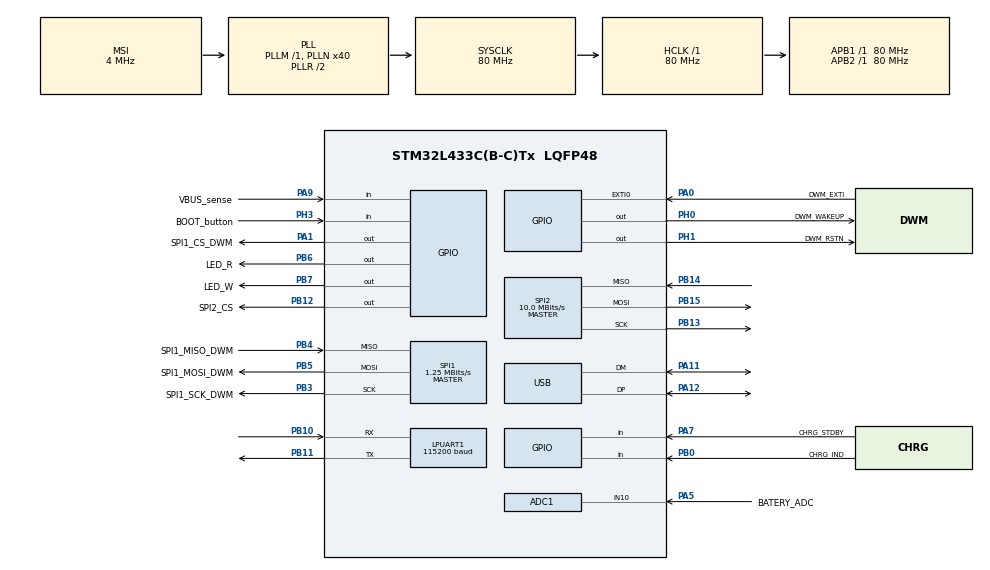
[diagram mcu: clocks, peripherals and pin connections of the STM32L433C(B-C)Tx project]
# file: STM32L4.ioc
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ADC1.Channel-1\#ChannelRegularConversion=ADC_CHANNEL_10
ADC1.ClockPrescaler=ADC_CLOCK_ASYNC_DIV256
ADC1.LowPowerAutoWait=ENABLE
ADC1.NbrOfConversionFlag=1
ADC1.OffsetNumber-1\#ChannelRegularConversion=ADC_OFFSET_NONE
ADC1.Rank-1\#ChannelRegularConversion=1
ADC1.Resolution=ADC_RESOLUTION_8B
ADC1.SamplingTime-1\#ChannelRegularConversion=ADC_SAMPLETIME_640CYCLES_5
ADC1.master=1
Dma.LPUART_RX.0.Direction=DMA_PERIPH_TO_MEMORY
Dma.LPUART_RX.0.Instance=DMA2_Channel7
Dma.LPUART_RX.0.MemDataAlignment=DMA_MDATAALIGN_BYTE
Dma.LPUART_RX.0.MemInc=DMA_MINC_ENABLE
Dma.LPUART_RX.0.Mode=DMA_NORMAL
Dma.LPUART_RX.0.PeriphDataAlignment=DMA_PDATAALIGN_BYTE
Dma.LPUART_RX.0.PeriphInc=DMA_PINC_DISABLE
Dma.LPUART_RX.0.Priority=DMA_PRIORITY_LOW
Dma.Request0=LPUART_RX
FREERTOS.Tasks01=defaultTask,24,128,StartDefaultTask,Default,NULL,Dynamic,NULL,NULL;Blink,8,256,StartBlink,As external,NULL,Dynamic,NULL,NULL;Accelerometer,24,512,StartAcc,As external,NULL,Dynamic,NULL,NULL;Ranging,40,2048,StartRangingTask,As external,NULL,Dynamic,NULL,NULL;mprinf,8,512,PrintTask,As external,NULL,Dynamic,NULL,NULL
FREERTOS.configENABLE_FPU=1
FREERTOS.configTOTAL_HEAP_SIZE=24576
FREERTOS.configUSE_NEWLIB_REENTRANT=1
FREERTOS.configUSE_TICKLESS_IDLE=1
IWDG.Prescaler=IWDG_PRESCALER_32
IWDG.Reload=3999
LPUART1.BaudRate=115200
LPUART1.WordLength=UART_WORDLENGTH_8B
Mcu.Family=STM32L4
Mcu.Name=STM32L433C(B-C)Tx
Mcu.Package=LQFP48
NVIC.DMA2_Channel7_IRQn=true\:5\:0\:false\:false\:true\:true\:false\:true\:true
NVIC.EXTI0_IRQn=true\:5\:0\:false\:false\:true\:true\:true\:true\:true
NVIC.LPTIM1_IRQn=true\:5\:0\:false\:false\:true\:true\:true\:true\:true
NVIC.PriorityGroup=NVIC_PRIORITYGROUP_4
NVIC.TIM6_DAC_IRQn=true\:15\:0\:false\:false\:true\:false\:false\:true\:true
NVIC.TimeBase=TIM6_DAC_IRQn
NVIC.TimeBaseIP=TIM6
NVIC.USB_IRQn=true\:6\:0\:true\:false\:true\:true\:false\:true\:true
PA0.GPIO_Label=DWM_EXTI
PA0.GPIO_PuPd=GPIO_NOPULL
PA0.Signal=GPXTI0
PA1.GPIO_Label=SPI1_CS_DWM
PA1.PinState=GPIO_PIN_SET
PA1.Signal=GPIO_Output
PA11.Mode=Device
PA11.Signal=USB_DM
PA12.Mode=Device
PA12.Signal=USB_DP
PA13\ (JTMS-SWDIO).GPIO_Label=Debug-SWDIO
PA13\ (JTMS-SWDIO).Mode=Serial_Wire
PA13\ (JTMS-SWDIO).Signal=SYS_JTMS-SWDIO
PA14\ (JTCK-SWCLK).GPIO_Label=Debug-SWCLK
PA14\ (JTCK-SWCLK).Mode=Serial_Wire
PA14\ (JTCK-SWCLK).Signal=SYS_JTCK-SWCLK
PA5.GPIO_Label=BATERY_ADC
PA5.Signal=ADCx_IN10
PA7.GPIO_Label=CHRG_STDBY
PA7.Signal=GPIO_Input
PA9.GPIO_Label=VBUS_sense
PA9.Signal=GPIO_Input
PB0.GPIO_Label=CHRG_IND
PB0.Signal=GPIO_Input
PB10.Mode=Asynchronous
PB10.Signal=LPUART1_RX
PB11.Mode=Asynchronous
PB11.Signal=LPUART1_TX
PB12.GPIO_Label=SPI2_CS
PB12.PinState=GPIO_PIN_SET
PB12.Signal=GPIO_Output
PB13.Mode=Full_Duplex_Master
PB13.Signal=SPI2_SCK
PB14.Mode=Full_Duplex_Master
PB14.Signal=SPI2_MISO
PB15.Mode=Full_Duplex_Master
PB15.Signal=SPI2_MOSI
PB3\ (JTDO-TRACESWO).GPIO_Label=SPI1_SCK_DWM
PB3\ (JTDO-TRACESWO).Mode=Full_Duplex_Master
PB3\ (JTDO-TRACESWO).Signal=SPI1_SCK
PB4\ (NJTRST).GPIO_Label=SPI1_MISO_DWM
PB4\ (NJTRST).Mode=Full_Duplex_Master
PB4\ (NJTRST).Signal=SPI1_MISO
PB5.GPIO_Label=SPI1_MOSI_DWM
PB5.Mode=Full_Duplex_Master
PB5.Signal=SPI1_MOSI
PB6.GPIO_Label=LED_R
PB6.Signal=GPIO_Output
PB7.GPIO_Label=LED_W
PB7.PinState=GPIO_PIN_RESET
PB7.Signal=GPIO_Output
PC13.GPIO_Label=SYS_WKUP2_ACC
PC13.Mode=SYS_WakeUp1
PC13.Signal=SYS_WKUP2
PC14-OSC32_IN\ (PC14).Mode=LSE-External-Clock-Source
PC14-OSC32_IN\ (PC14).Signal=RCC_OSC32_IN
PH0-OSC_IN\ (PH0).GPIO_Label=DWM_WAKEUP
PH0-OSC_IN\ (PH0).Signal=GPIO_Output
PH1-OSC_OUT\ (PH1).GPIO_Label=DWM_RSTN
PH1-OSC_OUT\ (PH1).GPIO_ModeDefaultOutputPP=GPIO_MODE_OUTPUT_OD
PH1-OSC_OUT\ (PH1).GPIO_PuPd=GPIO_NOPULL
PH1-OSC_OUT\ (PH1).Signal=GPIO_Output
PH3-BOOT0.GPIO_Label=BOOT_button
PH3-BOOT0.Signal=GPIO_Input
ProjectManager.HeapSize=0x200
ProjectManager.StackSize=0x400
ProjectManager.TargetToolchain=CMake
RCC.ADCFreq_Value=48000000
RCC.AHBFreq_Value=80000000
RCC.APB1Freq_Value=80000000
RCC.APB1TimFreq_Value=80000000
RCC.APB2Freq_Value=80000000
RCC.APB2TimFreq_Value=80000000
RCC.CK48CLockSelection=RCC_USBCLKSOURCE_HSI48
RCC.CortexFreq_Value=80000000
RCC.HCLKFreq_Value=80000000
RCC.HSE_VALUE=8000000
RCC.HSI48_VALUE=48000000
RCC.HSI_VALUE=16000000
RCC.LPTIM1CLockSelection=RCC_LPTIM1CLKSOURCE_LSE
RCC.LPTIM2CLockSelection=RCC_LPTIM2CLKSOURCE_LSE
RCC.LSE_Drive_CapabilityArg=+LSE_Drive_Capability
RCC.LSE_VALUE=32768
RCC.MSIAutoCalibration=ENABLED
RCC.MSI_VALUE=4000000
RCC.PLLN=40
RCC.PLLSAI1N=24
RCC.SYSCLKFreq_VALUE=80000000
RCC.SYSCLKSource=RCC_SYSCLKSOURCE_PLLCLK
RCC.USBFreq_Value=48000000
RCC.VCOOutputFreq_Value=160000000
SH.ADCx_IN10.0=ADC1_IN10,IN10-Single-Ended
SPI1.BaudRatePrescaler=SPI_BAUDRATEPRESCALER_64
SPI1.CalculateBaudRate=1.25 MBits/s
SPI1.DataSize=SPI_DATASIZE_8BIT
SPI1.Direction=SPI_DIRECTION_2LINES
SPI1.Mode=SPI_MODE_MASTER
SPI1.VirtualType=VM_MASTER
SPI2.BaudRatePrescaler=SPI_BAUDRATEPRESCALER_8
SPI2.CalculateBaudRate=10.0 MBits/s
SPI2.DataSize=SPI_DATASIZE_8BIT
SPI2.Direction=SPI_DIRECTION_2LINES
SPI2.Mode=SPI_MODE_MASTER
SPI2.NSSPMode=SPI_NSS_PULSE_DISABLE
SPI2.VirtualType=VM_MASTER
TIM2.Period=0xFFFFFFFF
TIM2.Prescaler=79
USB_DEVICE.CLASS_NAME_FS=CDC
USB_DEVICE.USBD_DEBUG_LEVEL=2
USB_DEVICE.VirtualMode=Cdc
USB_DEVICE.VirtualModeFS=Cdc_FS
VP_FREERTOS_VS_CMSIS_V2.Mode=CMSIS_V2
VP_IWDG_VS_IWDG.Mode=IWDG_Activate
VP_LPTIM1_VS_LPTIM_counterModeInternalClock.Mode=Counts__internal_clock_event_00
VP_SYS_VS_tim6.Mode=TIM6
VP_TIM2_VS_ClockSourceINT.Mode=Internal
VP_USB_DEVICE_VS_USB_DEVICE_CDC_FS.Mode=CDC_FS
board=custom

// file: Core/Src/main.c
/* USER CODE BEGIN Header */
/**
  ******************************************************************************
  * @file           : main.c
  * @brief          : Main program body
  ******************************************************************************
  * @attention
  *
  * Copyright (c) 2026 STMicroelectronics.
  * All rights reserved.
  *
  * This software is licensed under terms that can be found in the LICENSE file
  * in the root directory of this software component.
  * If no LICENSE file comes with this software, it is provided AS-IS.
  *
  ******************************************************************************
  */
/* USER CODE END Header */
#include "main.h"
#include "cmsis_os.h"
#include "usb_device.h"

/* USER CODE BEGIN Includes */
#include "lsm6dsv.h"
#include "blink.h"
#include "DWM3000.h"
#include "my_print.h"
/* USER CODE END Includes */

ADC_HandleTypeDef hadc1;

IWDG_HandleTypeDef hiwdg;

LPTIM_HandleTypeDef hlptim1;

UART_HandleTypeDef hlpuart1;
DMA_HandleTypeDef hdma_lpuart_rx;

SPI_HandleTypeDef hspi1;
SPI_HandleTypeDef hspi2;

TIM_HandleTypeDef htim2;

/* Definitions for defaultTask */
osThreadId_t defaultTaskHandle;
const osThreadAttr_t defaultTask_attributes = {
  .name = "defaultTask",
  .stack_size = 128 * 4,
  .priority = (osPriority_t) osPriorityNormal,
};
/* Definitions for Blink */
osThreadId_t BlinkHandle;
const osThreadAttr_t Blink_attributes = {
  .name = "Blink",
  .stack_size = 256 * 4,
  .priority = (osPriority_t) osPriorityLow,
};
/* Definitions for Accelerometer */
osThreadId_t AccelerometerHandle;
const osThreadAttr_t Accelerometer_attributes = {
  .name = "Accelerometer",
  .stack_size = 512 * 4,
  .priority = (osPriority_t) osPriorityNormal,
};
/* Definitions for Ranging */
osThreadId_t RangingHandle;
const osThreadAttr_t Ranging_attributes = {
  .name = "Ranging",
  .stack_size = 2048 * 4,
  .priority = (osPriority_t) osPriorityHigh,
};
/* Definitions for mprinf */
osThreadId_t mprinfHandle;
const osThreadAttr_t mprinf_attributes = {
  .name = "mprinf",
  .stack_size = 512 * 4,
  .priority = (osPriority_t) osPriorityLow,
};

void SystemClock_Config(void);
static void MX_GPIO_Init(void);
static void MX_DMA_Init(void);
static void MX_SPI1_Init(void);
static void MX_TIM2_Init(void);
static void MX_IWDG_Init(void);
static void MX_SPI2_Init(void);
static void MX_LPUART1_UART_Init(void);
static void MX_ADC1_Init(void);
static void MX_LPTIM1_Init(void);
void StartDefaultTask(void *argument);
extern void StartBlink(void *argument);
extern void StartAcc(void *argument);
extern void StartRangingTask(void *argument);
extern void PrintTask(void *argument);

/* USER CODE BEGIN PFP */
void ReinitAdc(void);
/* USER CODE END PFP */

int main(void)
{

  /* MCU Configuration--------------------------------------------------------*/

  /* Reset of all peripherals, Initializes the Flash interface and the Systick. */
  HAL_Init();

  /* Configure the system clock */
  SystemClock_Config();

  /* Initialize all configured peripherals */
  MX_GPIO_Init();
  MX_DMA_Init();
  MX_SPI1_Init();
  MX_TIM2_Init();
  MX_IWDG_Init();
  MX_SPI2_Init();
  MX_LPUART1_UART_Init();
  MX_ADC1_Init();
  MX_LPTIM1_Init();

  /* Init scheduler */
  osKernelInitialize();

  /* Create the thread(s) */
  /* creation of defaultTask */
  defaultTaskHandle = osThreadNew(StartDefaultTask, NULL, &defaultTask_attributes);

  /* creation of Blink */
  BlinkHandle = osThreadNew(StartBlink, NULL, &Blink_attributes);

  /* creation of Accelerometer */
  AccelerometerHandle = osThreadNew(StartAcc, NULL, &Accelerometer_attributes);

  /* creation of Ranging */
  RangingHandle = osThreadNew(StartRangingTask, NULL, &Ranging_attributes);

  /* creation of mprinf */
  mprinfHandle = osThreadNew(PrintTask, NULL, &mprinf_attributes);

  /* Start scheduler */
  osKernelStart();

  /* We should never get here as control is now taken by the scheduler */

  /* Infinite loop */
  while (1)
  {

  }
}

void SystemClock_Config(void)
{
  RCC_OscInitTypeDef RCC_OscInitStruct = {0};
  RCC_ClkInitTypeDef RCC_ClkInitStruct = {0};

  /** Configure the main internal regulator output voltage
  */
  if (HAL_PWREx_ControlVoltageScaling(PWR_REGULATOR_VOLTAGE_SCALE1) != HAL_OK)
  {
    Error_Handler();
  }

  /** Initializes the RCC Oscillators according to the specified parameters
  * in the RCC_OscInitTypeDef structure.
  */
  RCC_OscInitStruct.OscillatorType = RCC_OSCILLATORTYPE_HSI48|RCC_OSCILLATORTYPE_LSI
                              |RCC_OSCILLATORTYPE_LSE|RCC_OSCILLATORTYPE_MSI;
  RCC_OscInitStruct.LSEState = RCC_LSE_BYPASS;
  RCC_OscInitStruct.HSI48State = RCC_HSI48_ON;
  RCC_OscInitStruct.LSIState = RCC_LSI_ON;
  RCC_OscInitStruct.MSIState = RCC_MSI_ON;
  RCC_OscInitStruct.MSICalibrationValue = 0;
  RCC_OscInitStruct.MSIClockRange = RCC_MSIRANGE_6;
  RCC_OscInitStruct.PLL.PLLState = RCC_PLL_ON;
  RCC_OscInitStruct.PLL.PLLSource = RCC_PLLSOURCE_MSI;
  RCC_OscInitStruct.PLL.PLLM = 1;
  RCC_OscInitStruct.PLL.PLLN = 40;
  RCC_OscInitStruct.PLL.PLLP = RCC_PLLP_DIV7;
  RCC_OscInitStruct.PLL.PLLQ = RCC_PLLQ_DIV2;
  RCC_OscInitStruct.PLL.PLLR = RCC_PLLR_DIV2;
  if (HAL_RCC_OscConfig(&RCC_OscInitStruct) != HAL_OK)
  {
    Error_Handler();
  }

  /** Initializes the CPU, AHB and APB buses clocks
  */
  RCC_ClkInitStruct.ClockType = RCC_CLOCKTYPE_HCLK|RCC_CLOCKTYPE_SYSCLK
                              |RCC_CLOCKTYPE_PCLK1|RCC_CLOCKTYPE_PCLK2;
  RCC_ClkInitStruct.SYSCLKSource = RCC_SYSCLKSOURCE_PLLCLK;
  RCC_ClkInitStruct.AHBCLKDivider = RCC_SYSCLK_DIV1;
  RCC_ClkInitStruct.APB1CLKDivider = RCC_HCLK_DIV1;
  RCC_ClkInitStruct.APB2CLKDivider = RCC_HCLK_DIV1;

  if (HAL_RCC_ClockConfig(&RCC_ClkInitStruct, FLASH_LATENCY_4) != HAL_OK)
  {
    Error_Handler();
  }

  /** Enable MSI Auto calibration
  */
  HAL_RCCEx_EnableMSIPLLMode();
}

static void MX_ADC1_Init(void)
{

  ADC_ChannelConfTypeDef sConfig = {0};

  /** Common config
  */
  hadc1.Instance = ADC1;
  hadc1.Init.ClockPrescaler = ADC_CLOCK_ASYNC_DIV256;
  hadc1.Init.Resolution = ADC_RESOLUTION_8B;
  hadc1.Init.DataAlign = ADC_DATAALIGN_RIGHT;
  hadc1.Init.ScanConvMode = ADC_SCAN_DISABLE;
  hadc1.Init.EOCSelection = ADC_EOC_SINGLE_CONV;
  hadc1.Init.LowPowerAutoWait = ENABLE;
  hadc1.Init.ContinuousConvMode = DISABLE;
  hadc1.Init.NbrOfConversion = 1;
  hadc1.Init.DiscontinuousConvMode = DISABLE;
  hadc1.Init.ExternalTrigConv = ADC_SOFTWARE_START;
  hadc1.Init.ExternalTrigConvEdge = ADC_EXTERNALTRIGCONVEDGE_NONE;
  hadc1.Init.DMAContinuousRequests = DISABLE;
  hadc1.Init.Overrun = ADC_OVR_DATA_PRESERVED;
  hadc1.Init.OversamplingMode = DISABLE;
  if (HAL_ADC_Init(&hadc1) != HAL_OK)
  {
    Error_Handler();
  }

  /** Configure Regular Channel
  */
  sConfig.Channel = ADC_CHANNEL_10;
  sConfig.Rank = ADC_REGULAR_RANK_1;
  sConfig.SamplingTime = ADC_SAMPLETIME_640CYCLES_5;
  sConfig.SingleDiff = ADC_SINGLE_ENDED;
  sConfig.OffsetNumber = ADC_OFFSET_NONE;
  sConfig.Offset = 0;
  if (HAL_ADC_ConfigChannel(&hadc1, &sConfig) != HAL_OK)
  {
    Error_Handler();
  }

}

static void MX_IWDG_Init(void)
{

  hiwdg.Instance = IWDG;
  hiwdg.Init.Prescaler = IWDG_PRESCALER_32;
  hiwdg.Init.Window = 4095;
  hiwdg.Init.Reload = 3999;
  if (HAL_IWDG_Init(&hiwdg) != HAL_OK)
  {
    Error_Handler();
  }

}

static void MX_LPTIM1_Init(void)
{

  hlptim1.Instance = LPTIM1;
  hlptim1.Init.Clock.Source = LPTIM_CLOCKSOURCE_APBCLOCK_LPOSC;
  hlptim1.Init.Clock.Prescaler = LPTIM_PRESCALER_DIV1;
  hlptim1.Init.Trigger.Source = LPTIM_TRIGSOURCE_SOFTWARE;
  hlptim1.Init.OutputPolarity = LPTIM_OUTPUTPOLARITY_HIGH;
  hlptim1.Init.UpdateMode = LPTIM_UPDATE_IMMEDIATE;
  hlptim1.Init.CounterSource = LPTIM_COUNTERSOURCE_INTERNAL;
  hlptim1.Init.Input1Source = LPTIM_INPUT1SOURCE_GPIO;
  hlptim1.Init.Input2Source = LPTIM_INPUT2SOURCE_GPIO;
  if (HAL_LPTIM_Init(&hlptim1) != HAL_OK)
  {
    Error_Handler();
  }

}

static void MX_LPUART1_UART_Init(void)
{

  hlpuart1.Instance = LPUART1;
  hlpuart1.Init.BaudRate = 115200;
  hlpuart1.Init.WordLength = UART_WORDLENGTH_8B;
  hlpuart1.Init.StopBits = UART_STOPBITS_1;
  hlpuart1.Init.Parity = UART_PARITY_NONE;
  hlpuart1.Init.Mode = UART_MODE_TX_RX;
  hlpuart1.Init.HwFlowCtl = UART_HWCONTROL_NONE;
  hlpuart1.Init.OneBitSampling = UART_ONE_BIT_SAMPLE_DISABLE;
  hlpuart1.AdvancedInit.AdvFeatureInit = UART_ADVFEATURE_NO_INIT;
  if (HAL_UART_Init(&hlpuart1) != HAL_OK)
  {
    Error_Handler();
  }

}

static void MX_SPI1_Init(void)
{

  /* SPI1 parameter configuration*/
  hspi1.Instance = SPI1;
  hspi1.Init.Mode = SPI_MODE_MASTER;
  hspi1.Init.Direction = SPI_DIRECTION_2LINES;
  hspi1.Init.DataSize = SPI_DATASIZE_8BIT;
  hspi1.Init.CLKPolarity = SPI_POLARITY_LOW;
  hspi1.Init.CLKPhase = SPI_PHASE_1EDGE;
  hspi1.Init.NSS = SPI_NSS_SOFT;
  hspi1.Init.BaudRatePrescaler = SPI_BAUDRATEPRESCALER_64;
  hspi1.Init.FirstBit = SPI_FIRSTBIT_MSB;
  hspi1.Init.TIMode = SPI_TIMODE_DISABLE;
  hspi1.Init.CRCCalculation = SPI_CRCCALCULATION_DISABLE;
  hspi1.Init.CRCPolynomial = 7;
  hspi1.Init.CRCLength = SPI_CRC_LENGTH_DATASIZE;
  hspi1.Init.NSSPMode = SPI_NSS_PULSE_ENABLE;
  if (HAL_SPI_Init(&hspi1) != HAL_OK)
  {
    Error_Handler();
  }

}

static void MX_SPI2_Init(void)
{

  /* SPI2 parameter configuration*/
  hspi2.Instance = SPI2;
  hspi2.Init.Mode = SPI_MODE_MASTER;
  hspi2.Init.Direction = SPI_DIRECTION_2LINES;
  hspi2.Init.DataSize = SPI_DATASIZE_8BIT;
  hspi2.Init.CLKPolarity = SPI_POLARITY_LOW;
  hspi2.Init.CLKPhase = SPI_PHASE_1EDGE;
  hspi2.Init.NSS = SPI_NSS_SOFT;
  hspi2.Init.BaudRatePrescaler = SPI_BAUDRATEPRESCALER_8;
  hspi2.Init.FirstBit = SPI_FIRSTBIT_MSB;
  hspi2.Init.TIMode = SPI_TIMODE_DISABLE;
  hspi2.Init.CRCCalculation = SPI_CRCCALCULATION_DISABLE;
  hspi2.Init.CRCPolynomial = 7;
  hspi2.Init.CRCLength = SPI_CRC_LENGTH_DATASIZE;
  hspi2.Init.NSSPMode = SPI_NSS_PULSE_DISABLE;
  if (HAL_SPI_Init(&hspi2) != HAL_OK)
  {
    Error_Handler();
  }

}

static void MX_TIM2_Init(void)
{

  TIM_ClockConfigTypeDef sClockSourceConfig = {0};
  TIM_MasterConfigTypeDef sMasterConfig = {0};

  htim2.Instance = TIM2;
  htim2.Init.Prescaler = 79;
  htim2.Init.CounterMode = TIM_COUNTERMODE_UP;
  htim2.Init.Period = 0xFFFFFFFF;
  htim2.Init.ClockDivision = TIM_CLOCKDIVISION_DIV1;
  htim2.Init.AutoReloadPreload = TIM_AUTORELOAD_PRELOAD_DISABLE;
  if (HAL_TIM_Base_Init(&htim2) != HAL_OK)
  {
    Error_Handler();
  }
  sClockSourceConfig.ClockSource = TIM_CLOCKSOURCE_INTERNAL;
  if (HAL_TIM_ConfigClockSource(&htim2, &sClockSourceConfig) != HAL_OK)
  {
    Error_Handler();
  }
  sMasterConfig.MasterOutputTrigger = TIM_TRGO_RESET;
  sMasterConfig.MasterSlaveMode = TIM_MASTERSLAVEMODE_DISABLE;
  if (HAL_TIMEx_MasterConfigSynchronization(&htim2, &sMasterConfig) != HAL_OK)
  {
    Error_Handler();
  }
  /* USER CODE BEGIN TIM2_Init 2 */
HAL_TIM_Base_Start(&htim2);
  /* USER CODE END TIM2_Init 2 */

}

static void MX_DMA_Init(void)
{

  /* DMA controller clock enable */
  __HAL_RCC_DMA2_CLK_ENABLE();

  /* DMA interrupt init */
  /* DMA2_Channel7_IRQn interrupt configuration */
  HAL_NVIC_SetPriority(DMA2_Channel7_IRQn, 5, 0);
  HAL_NVIC_EnableIRQ(DMA2_Channel7_IRQn);

}

static void MX_GPIO_Init(void)
{
  GPIO_InitTypeDef GPIO_InitStruct = {0};

  /* GPIO Ports Clock Enable */
  __HAL_RCC_GPIOC_CLK_ENABLE();
  __HAL_RCC_GPIOH_CLK_ENABLE();
  __HAL_RCC_GPIOA_CLK_ENABLE();
  __HAL_RCC_GPIOB_CLK_ENABLE();

  /*Configure GPIO pin Output Level */
  HAL_GPIO_WritePin(GPIOH, DWM_WAKEUP_Pin|DWM_RSTN_Pin, GPIO_PIN_RESET);

  /*Configure GPIO pin Output Level */
  HAL_GPIO_WritePin(SPI1_CS_DWM_GPIO_Port, SPI1_CS_DWM_Pin, GPIO_PIN_SET);

  /*Configure GPIO pin Output Level */
  HAL_GPIO_WritePin(SPI2_CS_GPIO_Port, SPI2_CS_Pin, GPIO_PIN_SET);

  /*Configure GPIO pin Output Level */
  HAL_GPIO_WritePin(GPIOB, LED_R_Pin|LED_W_Pin, GPIO_PIN_RESET);

  /*Configure GPIO pin : DWM_WAKEUP_Pin */
  GPIO_InitStruct.Pin = DWM_WAKEUP_Pin;
  GPIO_InitStruct.Mode = GPIO_MODE_OUTPUT_PP;
  GPIO_InitStruct.Pull = GPIO_NOPULL;
  GPIO_InitStruct.Speed = GPIO_SPEED_FREQ_LOW;
  HAL_GPIO_Init(DWM_WAKEUP_GPIO_Port, &GPIO_InitStruct);

  /*Configure GPIO pin : DWM_RSTN_Pin */
  GPIO_InitStruct.Pin = DWM_RSTN_Pin;
  GPIO_InitStruct.Mode = GPIO_MODE_OUTPUT_OD;
  GPIO_InitStruct.Pull = GPIO_NOPULL;
  GPIO_InitStruct.Speed = GPIO_SPEED_FREQ_LOW;
  HAL_GPIO_Init(DWM_RSTN_GPIO_Port, &GPIO_InitStruct);

  /*Configure GPIO pin : DWM_EXTI_Pin */
  GPIO_InitStruct.Pin = DWM_EXTI_Pin;
  GPIO_InitStruct.Mode = GPIO_MODE_IT_RISING;
  GPIO_InitStruct.Pull = GPIO_NOPULL;
  HAL_GPIO_Init(DWM_EXTI_GPIO_Port, &GPIO_InitStruct);

  /*Configure GPIO pin : SPI1_CS_DWM_Pin */
  GPIO_InitStruct.Pin = SPI1_CS_DWM_Pin;
  GPIO_InitStruct.Mode = GPIO_MODE_OUTPUT_PP;
  GPIO_InitStruct.Pull = GPIO_NOPULL;
  GPIO_InitStruct.Speed = GPIO_SPEED_FREQ_LOW;
  HAL_GPIO_Init(SPI1_CS_DWM_GPIO_Port, &GPIO_InitStruct);

  /*Configure GPIO pins : CHRG_STDBY_Pin VBUS_sense_Pin */
  GPIO_InitStruct.Pin = CHRG_STDBY_Pin|VBUS_sense_Pin;
  GPIO_InitStruct.Mode = GPIO_MODE_INPUT;
  GPIO_InitStruct.Pull = GPIO_NOPULL;
  HAL_GPIO_Init(GPIOA, &GPIO_InitStruct);

  /*Configure GPIO pin : CHRG_IND_Pin */
  GPIO_InitStruct.Pin = CHRG_IND_Pin;
  GPIO_InitStruct.Mode = GPIO_MODE_INPUT;
  GPIO_InitStruct.Pull = GPIO_NOPULL;
  HAL_GPIO_Init(CHRG_IND_GPIO_Port, &GPIO_InitStruct);

  /*Configure GPIO pins : SPI2_CS_Pin LED_R_Pin LED_W_Pin */
  GPIO_InitStruct.Pin = SPI2_CS_Pin|LED_R_Pin|LED_W_Pin;
  GPIO_InitStruct.Mode = GPIO_MODE_OUTPUT_PP;
  GPIO_InitStruct.Pull = GPIO_NOPULL;
  GPIO_InitStruct.Speed = GPIO_SPEED_FREQ_LOW;
  HAL_GPIO_Init(GPIOB, &GPIO_InitStruct);

  /*Configure GPIO pin : BOOT_button_Pin */
  GPIO_InitStruct.Pin = BOOT_button_Pin;
  GPIO_InitStruct.Mode = GPIO_MODE_INPUT;
  GPIO_InitStruct.Pull = GPIO_NOPULL;
  HAL_GPIO_Init(BOOT_button_GPIO_Port, &GPIO_InitStruct);

  /* EXTI interrupt init*/
  HAL_NVIC_SetPriority(EXTI0_IRQn, 5, 0);
  HAL_NVIC_EnableIRQ(EXTI0_IRQn);

}

/* USER CODE BEGIN 4 */

void ReinitAdc(void)
{
    HAL_ADC_DeInit(&hadc1);
    MX_ADC1_Init();
}

/* USER CODE END 4 */

void StartDefaultTask(void *argument)
{
  /* init code for USB_DEVICE */
  MX_USB_DEVICE_Init();
  for(;;)
  {
    osDelay(1);
  }
}

void HAL_TIM_PeriodElapsedCallback(TIM_HandleTypeDef *htim)
{
  if (htim->Instance == TIM6)
  {
    HAL_IncTick();
  }
}

void Error_Handler(void)
{
  /* USER CODE BEGIN Error_Handler_Debug */
  /* User can add his own implementation to report the HAL error return state */
  __disable_irq();
  while (1)
  {
    HAL_GPIO_TogglePin(LED_R_GPIO_Port, LED_R_Pin);
    HAL_Delay(100);
  }
  /* USER CODE END Error_Handler_Debug */
}
